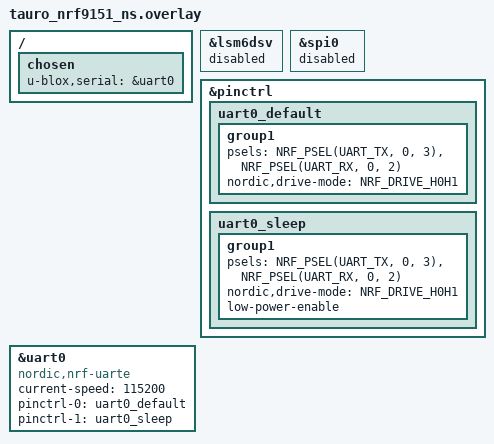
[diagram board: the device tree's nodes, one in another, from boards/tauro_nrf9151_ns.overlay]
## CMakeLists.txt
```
# SPDX-License-Identifier: Apache-2.0

cmake_minimum_required(VERSION 3.20.0)

# Infuse-IoT application
if(NOT infuse IN_LIST SNIPPET)
  set(SNIPPET infuse ${SNIPPET} CACHE STRING "" FORCE)
endif()

find_package(Zephyr REQUIRED HINTS $ENV{ZEPHYR_BASE})
project(ubx_serial_passthrough)

target_sources(app PRIVATE
  src/main.c
)
```

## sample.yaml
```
sample:
  description: Serial passthrough of raw UBX frames for u-center integration
  name: UBX Serial Passthrough
common:
  tags:
    - gnss
    - epacket
    - kv_store
    - logging
    - mcumgr
    - modem
    - modem_monitor
    - net
    - rpc
    - sensor
    - shared_device
    - states
    - tdf
tests:
  sample.gnss.ubx_serial_passthrough:
    build_only: true
    required_snippets:
      - infuse
    platform_allow:
      - tauro/nrf9151/ns
    integration_platforms:
      - tauro/nrf9151/ns
```

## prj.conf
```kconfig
CONFIG_INFUSE_SDK=y
CONFIG_GNSS_UBX_RAW_FRAME_HANDLER=y
CONFIG_SERIAL=y
CONFIG_UART_ASYNC_API=y
CONFIG_UART_0_ASYNC=y
CONFIG_UART_0_INTERRUPT_DRIVEN=n
```

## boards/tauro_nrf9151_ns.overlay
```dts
/ {
	chosen {
		u-blox,serial = &uart0;
		u-blox,serial = &uart0;
	};
};

/* Reclaim SPI0 to re-use as UART0 (No IMU) */
&lsm6dsv{
	status = "disabled";
};
&spi0 {
	status = "disabled";
};

/* Configure UART0 to the testpads */
&pinctrl {
	uart0_default: uart0_default {
		group1 {
			psels = <NRF_PSEL(UART_TX, 0, 3)>,
				<NRF_PSEL(UART_RX, 0, 2)>;
			nordic,drive-mode = <NRF_DRIVE_H0H1>;
		};
	};

	uart0_sleep: uart0_sleep {
		group1 {
			psels = <NRF_PSEL(UART_TX, 0, 3)>,
				<NRF_PSEL(UART_RX, 0, 2)>;
			nordic,drive-mode = <NRF_DRIVE_H0H1>;
			low-power-enable;
		};
	};
};

/* Enable UART0 */
&uart0 {
	compatible = "nordic,nrf-uarte";
	current-speed = <115200>;
	status = "okay";
	pinctrl-0 = <&uart0_default>;
	pinctrl-1 = <&uart0_sleep>;
	pinctrl-names = "default", "sleep";
};
```

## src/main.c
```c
/**
 * @file
 * @copyright 2024 Embeint Holdings Pty Ltd
 * @author Jordan Yates <jordan@embeint.com>
 *
 * SPDX-License-Identifier: FSL-1.1-ALv2
 */

#include <stdio.h>

#include <zephyr/kernel.h>
#include <zephyr/logging/log.h>
#include <zephyr/device.h>
#include <zephyr/drivers/uart.h>
#include <zephyr/net_buf.h>
#include <zephyr/pm/device_runtime.h>

#include <infuse/gnss/ubx/modem.h>
#include <infuse/gnss/ubx/cfg.h>
#include <infuse/gnss/ubx/protocol.h>

LOG_MODULE_REGISTER(app, LOG_LEVEL_INF);

struct uart_passthrough_state {
	struct ubx_modem_data *modem;
	uint8_t async_rx_buffer[2][512];
	volatile uint8_t async_rx_buffer_idx;
	bool forwarding;
} state;

NET_BUF_POOL_DEFINE(to_ubx_pool, 4, 512, 0, NULL);
K_FIFO_DEFINE(to_ubx_fifo);
K_SEM_DEFINE(uart_tx_done, 0, 1);

static void uart_callback(const struct device *dev, struct uart_event *evt, void *user_data)
{
	struct net_buf *buf;
	int rc;

	switch (evt->type) {
	case UART_TX_DONE:
		k_sem_give(&uart_tx_done);
		break;
	case UART_RX_BUF_REQUEST:
		rc = uart_rx_buf_rsp(dev, state.async_rx_buffer[state.async_rx_buffer_idx],
				     sizeof(state.async_rx_buffer[0]));
		__ASSERT_NO_MSG(rc == 0);
		state.async_rx_buffer_idx = !state.async_rx_buffer_idx ? 1 : 0;
		break;
	case UART_RX_RDY:
		/* Parse received data */
		LOG_HEXDUMP_DBG(evt->data.rx.buf + evt->data.rx.offset, evt->data.rx.len, "RX");

		buf = net_buf_alloc(&to_ubx_pool, K_NO_WAIT);
		if (buf == NULL) {
			LOG_ERR("No buffers remaining");
			return;
		}
		net_buf_add_mem(buf, evt->data.rx.buf + evt->data.rx.offset, evt->data.rx.len);
		k_fifo_put(&to_ubx_fifo, buf);
		break;
	case UART_RX_BUF_RELEASED:
		break;
	case UART_RX_DISABLED:
		break;
	default:
		LOG_WRN("Unhandled event: %d", evt->type);
	}
}

void ubx_modem_raw_frame_handler(struct ubx_frame *frame, uint16_t total_len)
{
	const struct device *uart = DEVICE_DT_GET(DT_CHOSEN(u_blox_serial));
	int rc;

	if (!state.forwarding) {
		return;
	}

	LOG_INF("UART<-UBX: %02x:%02x (%d bytes)", frame->message_class, frame->message_id,
		total_len);
	rc = uart_tx(uart, (void *)frame, total_len, SYS_FOREVER_US);
	if (rc != 0) {
		LOG_ERR("Failed to send (%d)", rc);
		return;
	}
	k_sem_take(&uart_tx_done, K_FOREVER);
}

int main(void)
{
	const struct device *uart = DEVICE_DT_GET(DT_CHOSEN(u_blox_serial));
	const struct device *gnss = DEVICE_DT_GET(DT_ALIAS(gnss));
	struct ubx_frame *frame;
	struct net_buf *buf;
	int rc;

	if (!device_is_ready(uart)) {
		LOG_ERR("UART %s not ready", uart->name);
		return -ENODEV;
	}
	if (!device_is_ready(gnss)) {
		LOG_ERR("GNSS %s not ready", gnss->name);
		return -ENODEV;
	}

	state.modem = ubx_modem_data_get(gnss);

	/* Power up UART and modem */
	rc = pm_device_runtime_get(uart);
	if (rc != 0) {
		LOG_ERR("Failed to request UART (%d)", rc);
		return rc;
	}
	rc = pm_device_runtime_get(gnss);
	if (rc != 0) {
		LOG_ERR("Failed to request GNSS (%d)", rc);
		return rc;
	}

	/* Configure RX */
	rc = uart_callback_set(uart, uart_callback, (void *)uart);
	if (rc != 0) {
		LOG_ERR("Failed to set callback (%d)", rc);
		return rc;
	}

	/* Permanently enable receiving */
	rc = uart_rx_enable(uart, state.async_rx_buffer[0], sizeof(state.async_rx_buffer[0]), 500);
	if (rc != 0) {
		LOG_ERR("Failed to enable RX (%d)", rc);
		return rc;
	}

	/* Enable forwarding of received frames */
	state.forwarding = true;

	for (;;) {
		buf = k_fifo_get(&to_ubx_fifo, K_FOREVER);

		rc = ubx_modem_send_async(state.modem, &buf->b, NULL, true);
		frame = (void *)buf->b.data;
		LOG_INF("UART->UBX: %02x:%02x (%d bytes)", frame->message_class, frame->message_id,
			buf->len);
		net_buf_unref(buf);
	}
	return 0;
}
```
